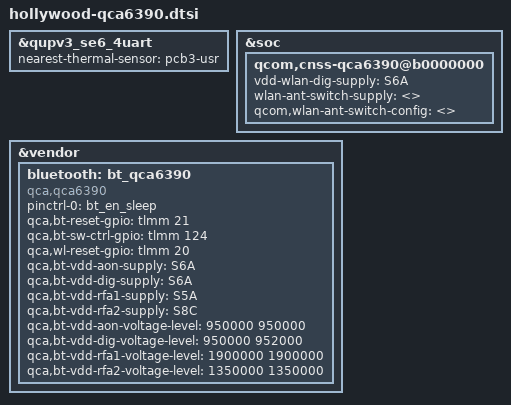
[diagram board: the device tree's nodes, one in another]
&qupv3_se6_4uart {
	status = "ok";
	nearest-thermal-sensor = "pcb3-usr";
};

&soc {
	qcom,cnss-qca6390@b0000000 {
		vdd-wlan-dig-supply = <&S6A>;
		wlan-ant-switch-supply = <>;
		qcom,wlan-ant-switch-config = <>;
	};
};

&vendor {
	bluetooth: bt_qca6390 {
		compatible = "qca,qca6390";
		pinctrl-names = "default";
		pinctrl-0 = <&bt_en_sleep>;
		qca,bt-reset-gpio = <&tlmm 21 0>; /* BT_EN */
		qca,bt-sw-ctrl-gpio = <&tlmm 124 0>; /* SW_CTRL */
		qca,wl-reset-gpio = <&tlmm 20 0>; /* WL_EN */
		qca,bt-vdd-aon-supply = <&S6A>;
		qca,bt-vdd-dig-supply = <&S6A>;
		qca,bt-vdd-rfa1-supply = <&S5A>;
		qca,bt-vdd-rfa2-supply = <&S8C>;

		qca,bt-vdd-aon-voltage-level = <950000 950000>;
		qca,bt-vdd-dig-voltage-level = <950000 952000>;
		qca,bt-vdd-rfa1-voltage-level = <1900000 1900000>;
		qca,bt-vdd-rfa2-voltage-level = <1350000 1350000>;
	};
};
